AUTOSAR XML (schema 4-2-2)
package /STELLANTIS/EPT/ASWCs
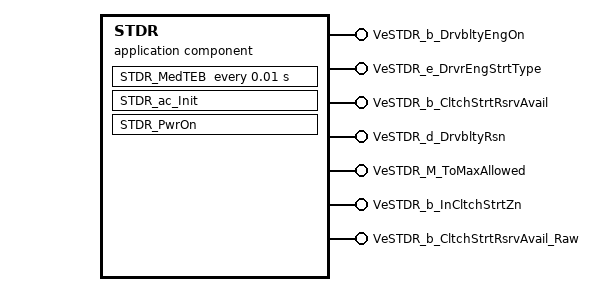
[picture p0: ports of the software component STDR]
  application sw component type STDR
    7 x provide port:
      VeSTDR_b_DrvbltyEngOn: nonqueued-sender-com-spec{data-element=Value, init-value=0}, provided-interface=VeSTDR_b_DrvbltyEngOn
      VeSTDR_e_DrvrEngStrtType: nonqueued-sender-com-spec{data-element=Value, init-value=CeSTRR_e_NoAction}, provided-interface=VeSTDR_e_DrvrEngStrtType
      VeSTDR_b_CltchStrtRsrvAvail: nonqueued-sender-com-spec{data-element=Value, init-value=0}, provided-interface=VeSTDR_b_CltchStrtRsrvAvail
      VeSTDR_d_DrvbltyRsn: nonqueued-sender-com-spec{data-element=Value, init-value=0}, provided-interface=VeSTDR_d_DrvbltyRsn
      VeSTDR_M_ToMaxAllowed: nonqueued-sender-com-spec{data-element=Value, init-value=0}, provided-interface=VeSTDR_M_ToMaxAllowed
      VeSTDR_b_InCltchStrtZn: nonqueued-sender-com-spec{data-element=Value, init-value=0}, provided-interface=VeSTDR_b_InCltchStrtZn
      VeSTDR_b_CltchStrtRsrvAvail_Raw: nonqueued-sender-com-spec{data-element=Value, init-value=0}, provided-interface=VeSTDR_b_CltchStrtRsrvAvail_Raw
    behavior IB_STDR: data-type-mapping=msADTtoIDTMapping, handle-termination-and-restart=NO-SUPPORT, included-data-type-set=data-type=TeOPTR_e_OptType
      timing event Event_MedTEB: start-on-event=STDR_MedTEB, period=0.01
      init event Event_STDR_ac_Init: start-on-event=STDR_ac_Init
      init event Event_PwrOn: start-on-event=STDR_PwrOn
      explicit-inter-runnable-variables:
        5 x data, all with category=VALUE, sw-calibration-access=READ-ONLY, type=Float, init-value=0:
          ToMax_write_IRV
          ToMax_P1f_P1P2p5_write_IRV
          ToMaxTotPwr_write_IRV
          BoostCnvr_DschrgPwrLim_IRV
          PbattMax_wirte_IRV
      runnable STDR_ac_Init
        data-send-points:
          access OUT_VeSTDR_e_DrvrEngStrtType_Value: accessed-variable=VeSTDR_e_DrvrEngStrtType.Value
      runnable STDR_MedTEB
        data-send-points:
          7 x access:
            OUT_VeSTDR_b_DrvbltyEngOn_Value: accessed-variable=VeSTDR_b_DrvbltyEngOn.Value
            OUT_VeSTDR_e_DrvrEngStrtType_Value: accessed-variable=VeSTDR_e_DrvrEngStrtType.Value
            OUT_VeSTDR_b_CltchStrtRsrvAvail_Value: accessed-variable=VeSTDR_b_CltchStrtRsrvAvail.Value
            OUT_VeSTDR_d_DrvbltyRsn_Value: accessed-variable=VeSTDR_d_DrvbltyRsn.Value
            OUT_VeSTDR_M_ToMaxAllowed_Value: accessed-variable=VeSTDR_M_ToMaxAllowed.Value
            OUT_VeSTDR_b_InCltchStrtZn_Value: accessed-variable=VeSTDR_b_InCltchStrtZn.Value
            OUT_VeSTDR_b_CltchStrtRsrvAvail_Raw_Value: accessed-variable=VeSTDR_b_CltchStrtRsrvAvail_Raw.Value
        written-local-variables:
          access WV_BoostCnvr_DschrgPwrLim_IRV: accessed-variable=BoostCnvr_DschrgPwrLim_IRV
          access WV_PbattMax_wirte_IRV: accessed-variable=PbattMax_wirte_IRV
      runnable STDR_PwrOn
        data-send-points:
          7 x access:
            OUT_VeSTDR_b_DrvbltyEngOn_Value: accessed-variable=VeSTDR_b_DrvbltyEngOn.Value
            OUT_VeSTDR_e_DrvrEngStrtType_Value: accessed-variable=VeSTDR_e_DrvrEngStrtType.Value
            OUT_VeSTDR_b_CltchStrtRsrvAvail_Value: accessed-variable=VeSTDR_b_CltchStrtRsrvAvail.Value
            OUT_VeSTDR_d_DrvbltyRsn_Value: accessed-variable=VeSTDR_d_DrvbltyRsn.Value
            OUT_VeSTDR_M_ToMaxAllowed_Value: accessed-variable=VeSTDR_M_ToMaxAllowed.Value
            OUT_VeSTDR_b_InCltchStrtZn_Value: accessed-variable=VeSTDR_b_InCltchStrtZn.Value
            OUT_VeSTDR_b_CltchStrtRsrvAvail_Raw_Value: accessed-variable=VeSTDR_b_CltchStrtRsrvAvail_Raw.Value
        written-local-variables:
          5 x access:
            WV_BoostCnvr_DschrgPwrLim_IRV: accessed-variable=BoostCnvr_DschrgPwrLim_IRV
            WV_PbattMax_wirte_IRV: accessed-variable=PbattMax_wirte_IRV
            WV_ToMaxTotPwr_write_IRV: accessed-variable=ToMaxTotPwr_write_IRV
            WV_ToMax_P1f_P1P2p5_write_IRV: accessed-variable=ToMax_P1f_P1P2p5_write_IRV
            WV_ToMax_write_IRV: accessed-variable=ToMax_write_IRV
      17 x variation point proxy, all with category=CONDITION:
        Variant_HSCL_BstConvEnbl: condition-access=0
        Variant_OPTL_3MtrEnbl: condition-access=0
        Variant_OPTL_ABPtsEnbl: condition-access=1
        Variant_OPTL_EPtsEnbl: condition-access=1
        Variant_OPTL_HPtEnbl: condition-access=1
        Variant_OPTL_HPtEnbl_ToMinMax: condition-access=1
        Variant_OPTL_LegacyModeCnst: condition-access=1
        Variant_STDR_EMshift_Enabled: condition-access=0
        Variant_STDR_FUNCTIONAL: condition-access=0
        Variant_STDR_FUNC_{1..7}: condition-access=0
        Variant_STDR_PBattMaxCrrctr: condition-access=0
